VERSION ""

NS_ :

BS_:

BU_: CPU HydPumpInverter_Inverter
VAL_TABLE_ ErrorDescription 65280 " Device specific " 61440 " Additional Functions " 36864 " External Error " 33360 " RPDO timeout " 33344 " Unexpected SYNC data length " 33328 " DAM MPDO not processed destination object not available " 33312 " PDO length exceeded " 33296 " PDO not processed due to length error " 33280 " Protocol Error " 33104 " CAN-ID collision " 33088 " recovered from bus off " 33072 " Life Guard Error or Heartbeat Error " 33056 " CAN in Error Passive Mode " 33040 " CAN Overrun (Objects lost) " 33024 " Communication " 32768 " Monitoring " 28672 " Additional Modules " 25344 " Data Set " 25088 " User Software " 24832 " Internal Software " 24576 " Device Software " 20480 " Device Hardware " 16896 " Device Temperature " 16640 " Ambient Temperature " 16384 " Temperature " 13056 " Output Voltage " 12800 " Voltage inside the device " 12544 " Mains Voltage " 12288 " Voltage " 8960 " Current device output side " 8704 " Current inside the device " 8448 " Current device input side " 8192 " Current " 4096 " Generic Error " 0 " error Reset or No Error " ;
VAL_TABLE_ NTM_Functions 130 "Reset Communication" 129 "Reset Node" 128 "Go in Pre-Operational Status" 2 "Go in Operational Status" 1 "Go in Operational Status" ;
VAL_TABLE_ NodeStatusTable 127 "PreOperational" 5 "Operational" 4 "Stopped" 0 "Boot" ;

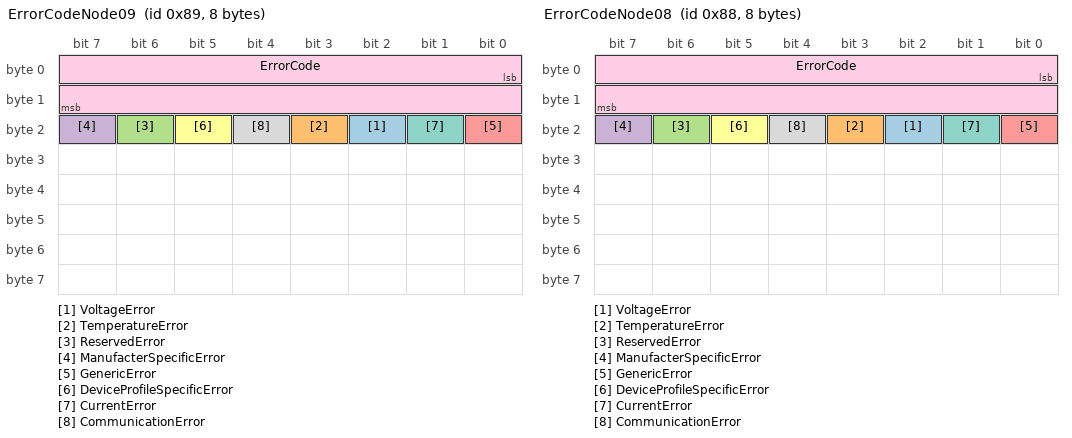
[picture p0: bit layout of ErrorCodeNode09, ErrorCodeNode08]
BO_ 137 ErrorCodeNode09: 8 Vector__XXX
 SG_ VoltageError : 18|1@1+ (1,0) [0|0] "" Vector__XXX
 SG_ TemperatureError : 19|1@1+ (1,0) [0|0] "" Vector__XXX
 SG_ ReservedError : 22|1@1+ (1,0) [0|0] "" Vector__XXX
 SG_ ManufacterSpecificError : 23|1@1+ (1,0) [0|0] "" Vector__XXX
 SG_ GenericError : 16|1@1+ (1,0) [0|0] "" Vector__XXX
 SG_ DeviceProfileSpecificError : 21|1@1+ (1,0) [0|0] "" Vector__XXX
 SG_ CurrentError : 17|1@1+ (1,0) [0|0] "" Vector__XXX
 SG_ CommunicationError : 20|1@1+ (1,0) [0|0] "" Vector__XXX
 SG_ ErrorCode : 0|16@1+ (1,0) [0|0] "" Vector__XXX

BO_ 136 ErrorCodeNode08: 8 Vector__XXX
 SG_ VoltageError : 18|1@1+ (1,0) [0|0] "" Vector__XXX
 SG_ TemperatureError : 19|1@1+ (1,0) [0|0] "" Vector__XXX
 SG_ ReservedError : 22|1@1+ (1,0) [0|0] "" Vector__XXX
 SG_ ManufacterSpecificError : 23|1@1+ (1,0) [0|0] "" Vector__XXX
 SG_ GenericError : 16|1@1+ (1,0) [0|0] "" Vector__XXX
 SG_ DeviceProfileSpecificError : 21|1@1+ (1,0) [0|0] "" Vector__XXX
 SG_ CurrentError : 17|1@1+ (1,0) [0|0] "" Vector__XXX
 SG_ CommunicationError : 20|1@1+ (1,0) [0|0] "" Vector__XXX
 SG_ ErrorCode : 0|16@1+ (1,0) [0|0] "" Vector__XXX

BO_ 0 NTM: 8 Vector__XXX
 SG_ NTM_Function : 0|8@1+ (1,0) [0|0] "" Vector__XXX
 SG_ NTM_AddressedNode : 8|8@1+ (1,0) [0|0] "" Vector__XXX

BO_ 1801 GUARDNode09: 1 Vector__XXX
 SG_ StatusNode : 0|8@1- (1,0) [0|0] "" Vector__XXX

BO_ 1800 GUARDNode08: 1 Vector__XXX
 SG_ StatusNode : 0|8@1- (1,0) [0|0] "" Vector__XXX

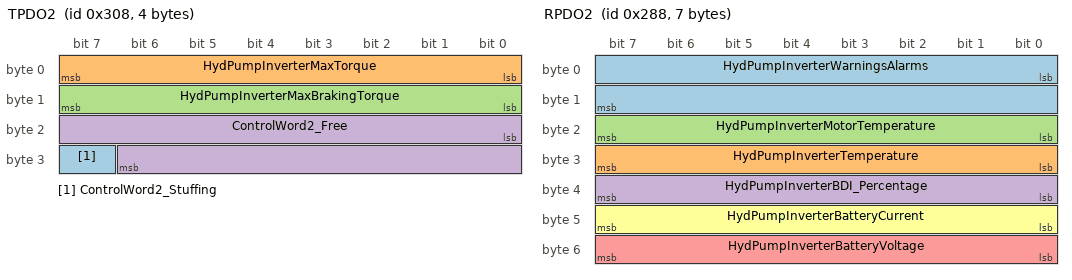
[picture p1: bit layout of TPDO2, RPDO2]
BO_ 776 TPDO2: 4 Vector__XXX
 SG_ ControlWord2_Stuffing : 31|1@1+ (1,0) [0|0] "" Vector__XXX
 SG_ HydPumpInverterMaxTorque : 0|8@1+ (1,0) [0|0] "" Vector__XXX
 SG_ HydPumpInverterMaxBrakingTorque : 8|8@1+ (1,0) [0|0] "" Vector__XXX
 SG_ ControlWord2_Free : 16|15@1+ (1,0) [0|0] "" Vector__XXX

BO_ 648 RPDO2: 7 Vector__XXX
 SG_ HydPumpInverterWarningsAlarms : 0|16@1+ (1,0) [0|0] "" Vector__XXX
 SG_ HydPumpInverterTemperature : 24|8@1- (1,0) [0|0] "" Vector__XXX
 SG_ HydPumpInverterMotorTemperature : 16|8@1+ (1,0) [0|0] "" Vector__XXX
 SG_ HydPumpInverterBDI_Percentage : 32|8@1+ (1,0) [0|0] "" Vector__XXX
 SG_ HydPumpInverterBatteryVoltage : 48|8@1+ (1,0) [0|0] "" Vector__XXX
 SG_ HydPumpInverterBatteryCurrent : 40|8@1+ (1,0) [0|0] "" Vector__XXX

BO_ 128 SYNC: 8 CPU

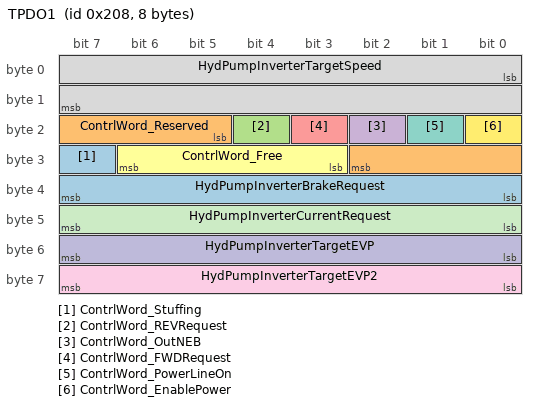
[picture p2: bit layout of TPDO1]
BO_ 520 TPDO1: 8 CPU
 SG_ ContrlWord_Stuffing : 31|1@1+ (1,0) [0|0] "" Vector__XXX
 SG_ ContrlWord_Reserved : 21|6@1+ (1,0) [0|0] "" Vector__XXX
 SG_ ContrlWord_REVRequest : 20|1@1+ (1,0) [0|0] "" Vector__XXX
 SG_ ContrlWord_OutNEB : 18|1@1+ (1,0) [0|0] "" Vector__XXX
 SG_ ContrlWord_FWDRequest : 19|1@1+ (1,0) [0|0] "" Vector__XXX
 SG_ ContrlWord_Free : 27|4@1+ (1,0) [0|0] "" Vector__XXX
 SG_ ContrlWord_PowerLineOn : 17|1@1+ (1,1) [0|0] "" Vector__XXX
 SG_ HydPumpInverterTargetSpeed : 0|16@1- (1,0) [0|0] "" Vector__XXX
 SG_ HydPumpInverterTargetEVP2 : 56|8@1+ (1,0) [0|0] "" Vector__XXX
 SG_ HydPumpInverterTargetEVP : 48|8@1+ (1,0) [0|0] "" Vector__XXX
 SG_ HydPumpInverterCurrentRequest : 40|8@1+ (1,0) [0|0] "" Vector__XXX
 SG_ ContrlWord_EnablePower : 16|1@1+ (1,0) [0|0] "" Vector__XXX
 SG_ HydPumpInverterBrakeRequest : 32|8@1+ (1,0) [0|0] "" Vector__XXX

BO_ 392 RPDO1: 8 Vector__XXX
 SG_ StatusWord_Stuffing : 31|1@1- (1,0) [0|0] "" Vector__XXX
 SG_ StatusWord_SensAcquiEndSuccess : 30|1@1- (1,0) [0|0] "" Vector__XXX
 SG_ StatusWord_SensAcqInProgress : 29|1@1- (1,0) [0|0] "" Vector__XXX
 SG_ StatusWord_Reserved : 18|4@1- (1,0) [0|0] "" Vector__XXX
 SG_ StatusWord_OutNEBStatus : 17|1@1- (1,0) [0|0] "" Vector__XXX
 SG_ StatusWord_A6 : 24|1@1- (1,0) [0|0] "" Vector__XXX
 SG_ StatusWord_A5 : 23|1@1- (1,0) [0|0] "" Vector__XXX
 SG_ StatusWord_A4 : 22|1@1- (1,0) [0|0] "" Vector__XXX
 SG_ StatusWord_A3 : 28|1@1- (1,0) [0|0] "" Vector__XXX
 SG_ StatusWord_A19 : 26|1@1- (1,0) [0|0] "" Vector__XXX
 SG_ StatusWord_A13 : 25|1@1- (1,0) [0|0] "" Vector__XXX
 SG_ StatusWord_A10 : 27|1@1- (1,0) [0|0] "" Vector__XXX
 SG_ StatusWord_OutNMCStatus : 16|1@1- (1,0) [0|0] ""  HydPumpInverter_Inverter
 SG_ HydPumpInverterStatusByte : 32|8@1+ (1,0) [0|0] ""  HydPumpInverter_Inverter
 SG_ HydPumpInverterAnalogInput2 : 48|8@1+ (1,0) [0|0] ""  HydPumpInverter_Inverter
 SG_ HydPumpInverterAnalogInput1 : 40|8@1+ (1,0) [0|0] ""  HydPumpInverter_Inverter
 SG_ HydPumpInverterActualCurrent : 56|8@1+ (1,0) [0|0] ""  HydPumpInverter_Inverter
 SG_ HydPumpInverterActualSpeed : 0|16@1- (1,0) [0|0] ""  HydPumpInverter_Inverter

BA_DEF_  "BusType" STRING ;
BA_DEF_DEF_  "BusType" "";
BA_ "BusType" "CAN";
VAL_ 137 ErrorCode 65280 " Device specific " 61440 " Additional Functions " 36864 " External Error " 33360 " RPDO timeout " 33344 " Unexpected SYNC data length " 33328 " DAM MPDO not processed destination object not available " 33312 " PDO length exceeded " 33296 " PDO not processed due to length error " 33280 " Protocol Error " 33104 " CAN-ID collision " 33088 " recovered from bus off " 33072 " Life Guard Error or Heartbeat Error " 33056 " CAN in Error Passive Mode " 33040 " CAN Overrun (Objects lost) " 33024 " Communication " 32768 " Monitoring " 28672 " Additional Modules " 25344 " Data Set " 25088 " User Software " 24832 " Internal Software " 24576 " Device Software " 20480 " Device Hardware " 16896 " Device Temperature " 16640 " Ambient Temperature " 16384 " Temperature " 13056 " Output Voltage " 12800 " Voltage inside the device " 12544 " Mains Voltage " 12288 " Voltage " 8960 " Current device output side " 8704 " Current inside the device " 8448 " Current device input side " 8192 " Current " 4096 " Generic Error " 0 " error Reset or No Error " ;
VAL_ 136 ErrorCode 65280 " Device specific " 61440 " Additional Functions " 36864 " External Error " 33360 " RPDO timeout " 33344 " Unexpected SYNC data length " 33328 " DAM MPDO not processed destination object not available " 33312 " PDO length exceeded " 33296 " PDO not processed due to length error " 33280 " Protocol Error " 33104 " CAN-ID collision " 33088 " recovered from bus off " 33072 " Life Guard Error or Heartbeat Error " 33056 " CAN in Error Passive Mode " 33040 " CAN Overrun (Objects lost) " 33024 " Communication " 32768 " Monitoring " 28672 " Additional Modules " 25344 " Data Set " 25088 " User Software " 24832 " Internal Software " 24576 " Device Software " 20480 " Device Hardware " 16896 " Device Temperature " 16640 " Ambient Temperature " 16384 " Temperature " 13056 " Output Voltage " 12800 " Voltage inside the device " 12544 " Mains Voltage " 12288 " Voltage " 8960 " Current device output side " 8704 " Current inside the device " 8448 " Current device input side " 8192 " Current " 4096 " Generic Error " 0 " error Reset or No Error " ;
VAL_ 0 NTM_Function 130 "Reset Communication" 129 "Reset Node" 128 "Go in Pre-Operational Status" 2 "Go in Operational Status" 1 "Go in Operational Status" ;
VAL_ 1801 StatusNode 127 "PreOperational" 5 "Operational" 4 "Stopped" 0 "Boot" ;
VAL_ 1800 StatusNode 127 "PreOperational" 5 "Operational" 4 "Stopped" 0 "Boot" ;
